AUTOSAR XML (schema 4-2-1)
package /ComponentTypes
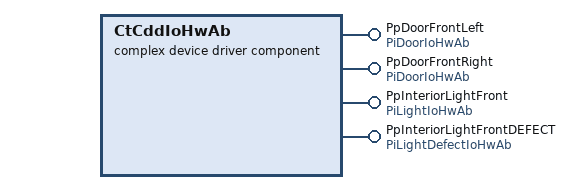
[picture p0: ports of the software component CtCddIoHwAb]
  complex device driver sw component type CtCddIoHwAb
    4 x provide port:
      PpDoorFrontLeft: server-com-spec{operation=ReadChannel, queue-length=1}, provided-interface=PiDoorIoHwAb
      PpDoorFrontRight: server-com-spec{operation=ReadChannel, queue-length=1}, provided-interface=PiDoorIoHwAb
      PpInteriorLightFront: server-com-spec{operation=WriteChannel, queue-length=1}, provided-interface=PiLightIoHwAb
      PpInteriorLightFrontDEFECT: server-com-spec{operation=ReadChannel, queue-length=1}, provided-interface=PiLightDefectIoHwAb
    behavior CtCddIoHwAb_InternalBehavior
      4 x operation invoked event:
        OIT_RCtCddIoHwAb_PpDoorFrontLeft_ReadChannel_PpDoorFrontLeft_ReadChannel: start-on-event=RCtCddIoHwAb_PpDoorFrontLeft_ReadChannel, operation=PpDoorFrontLeft.ReadChannel
        OIT_RCtCddIoHwAb_PpDoorFrontRight_ReadChannel_PpDoorFrontRight_ReadChannel: start-on-event=RCtCddIoHwAb_PpDoorFrontRight_ReadChannel, operation=PpDoorFrontRight.ReadChannel
        OIT_RCtCddIoHwAb_PpInteriorLightFront_WriteChannel_PpInteriorLightFront_WriteChannel: start-on-event=RCtCddIoHwAb_PpInteriorLightFront_WriteChannel, operation=PpInteriorLightFront.WriteChannel
        OIT_RCtCddIoHwAb_PpInteriorLightFrontDEFECT_ReadChannel_PpInteriorLightFrontDEFECT_ReadChannel: start-on-event=RCtCddIoHwAb_PpInteriorLightFrontDEFECT_ReadChannel, operation=PpInteriorLightFrontDEFECT.ReadChannel
      4 x runnable:
        RCtCddIoHwAb_PpDoorFrontLeft_ReadChannel
        RCtCddIoHwAb_PpDoorFrontRight_ReadChannel
        RCtCddIoHwAb_PpInteriorLightFront_WriteChannel
        RCtCddIoHwAb_PpInteriorLightFrontDEFECT_ReadChannel
  swc implementation CtCddIoHwAb_Implementation: behavior=CtCddIoHwAb_InternalBehavior
    code-descriptors:
      code Default: artifact-descriptors=autosar-engineering-object={short-label=Default, category=SWSRC}
